# ET6801 register map
Vendor: ETMCU Inc.; File version: v0.0.1
CPU: CM7 r2p1, little endian, MPU, FPU, I-cache, D-cache, ITCM, DTCM, 4 interrupt priority bits
Registers are 32-bit, read-write, reset 0x0 unless marked. A register's access mark holds for its fields unless they carry their own. Offsets are from the block's base; [hi:lo] are bit positions; {n}, {i} and the like mark numbered series.

## NVIC_STIR — Nested vectored interrupt controller
Base 0xE000EF00
0x00 STIR — Software trigger interrupt register
  [8:0] INTID — Software generated interrupt ID

## FPU_CPACR — Floating point unit CPACR
Base 0xE000ED88
0x00 CPACR — Coprocessor access control register
  [23:20] CP

## SCB_ACTRL — System control block ACTLR
Base 0xE000E008
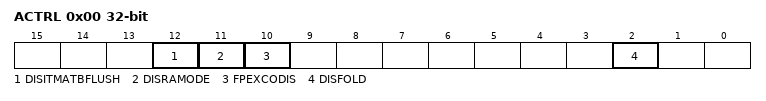
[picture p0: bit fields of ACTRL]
0x00 ACTRL — Auxiliary control register
  [12] DISITMATBFLUSH, [11] DISRAMODE, [10] FPEXCODIS, [2] DISFOLD

## FPU — Floting point unit
Base 0xE000EF34
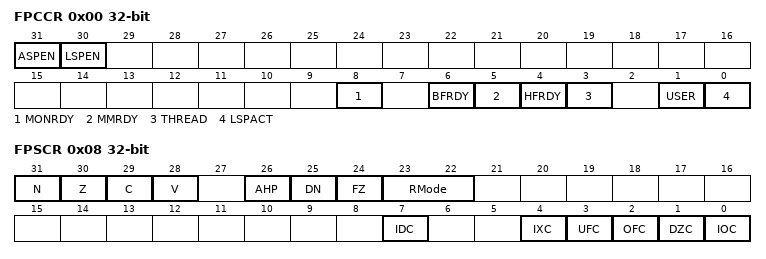
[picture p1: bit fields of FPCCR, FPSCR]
0x00 FPCCR — Floating-point context control register
  [31] ASPEN, [30] LSPEN, [8] MONRDY, [6] BFRDY, [5] MMRDY, [4] HFRDY, [3] THREAD, [1] USER, [0] LSPACT
0x04 FPCAR — Floating-point context address register
  [31:3] ADDRESS — Location of unpopulated floating-point
0x08 FPSCR — Floating-point status control register
  [31] N — Negative condition code flag
  [30] Z — Zero condition code flag
  [29] C — Carry condition code flag
  [28] V — Overflow condition code flag
  [26] AHP — Alternative half-precision control bit
  [25] DN — Default NaN mode control bit
  [24] FZ — Flush-to-zero mode control bit:
  [23:22] RMode — Rounding Mode control field
  [7] IDC — Input denormal cumulative exception bit.
  [4] IXC — Inexact cumulative exception bit
  [3] UFC — Underflow cumulative exception bit
  [2] OFC — Overflow cumulative exception bit
  [1] DZC — Division by zero cumulative exception bit.
  [0] IOC — Invalid operation cumulative exception bit

## PF — Processor features
Base 0xE000ED78
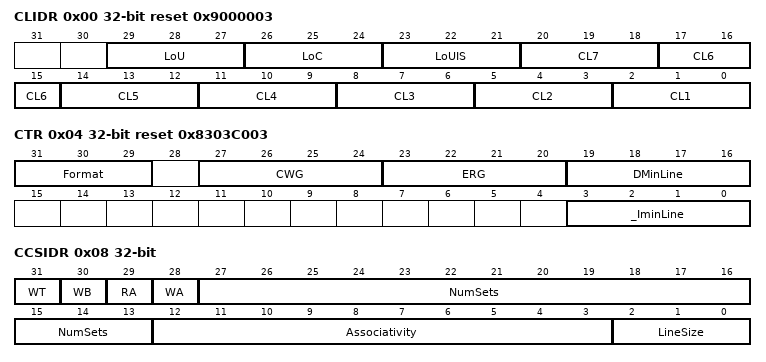
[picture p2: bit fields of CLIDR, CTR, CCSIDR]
0x00 CLIDR ro reset 0x9000003 — Cache Level ID register
  [29:27] LoU, [26:24] LoC, [23:21] LoUIS, [3n-1:3n-3] CL{n} (n=1..7)
0x04 CTR ro reset 0x8303C003 — Cache Type register
  [31:29] Format, [27:24] CWG, [23:20] ERG, [19:16] DMinLine, [3:0] _IminLine
0x08 CCSIDR ro — Cache Size ID register
  [31] WT, [30] WB, [29] RA, [28] WA, [27:13] NumSets, [12:3] Associativity, [2:0] LineSize

## NVIC — Nested Vectored Interrupt Controller
Base 0xE000E100
{0x0+4i} ISER{i} (i=0..3) — Interrupt Set-Enable Register
  [31:0] SETENA
{0x80+4i} ICER{i} (i=0..3) — Interrupt Clear-Enable Register
  [31:0] CLRENA
{0x100+4i} ISPR{i} (i=0..3) — Interrupt Set-Pending Register
  [31:0] SETPEND
{0x180+4i} ICPR{i} (i=0..3) — Interrupt Clear-Pending Register
  [31:0] CLRPEND
{0x200+4i} IABR{i} ro (i=0..3) — Interrupt Active Bit Register
  [31:0] ACTIVE
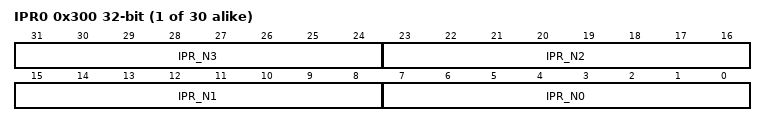
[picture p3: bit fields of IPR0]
{0x300+4i} IPR{i} (i=0..29) — Interrupt Priority Register
  [8n+7:8n] IPR_N{n} (n=0..3)

## MPU — Memory protection unit
Base 0xE000ED90
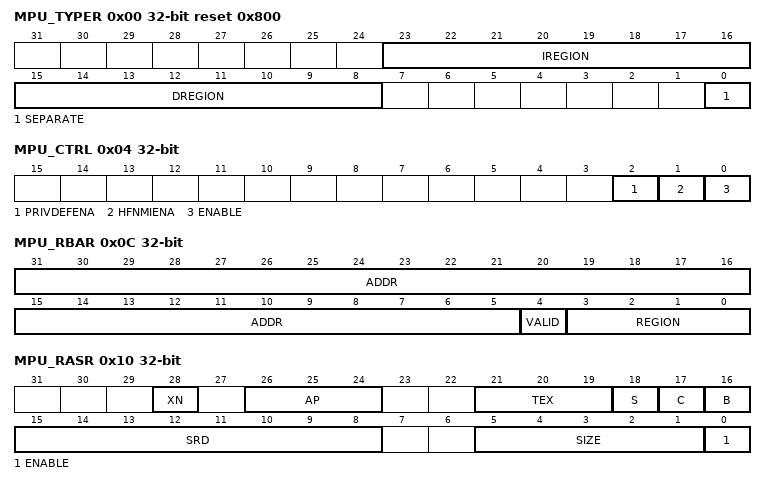
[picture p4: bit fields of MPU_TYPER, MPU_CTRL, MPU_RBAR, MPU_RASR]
0x00 MPU_TYPER ro reset 0x800 — MPU type register
  [23:16] IREGION — Number of MPU instruction regions
  [15:8] DREGION — Number of MPU data regions
  [0] SEPARATE — Separate flag
0x04 MPU_CTRL ro — MPU control register
  [2] PRIVDEFENA — Enable priviliged software access to default memory map
  [1] HFNMIENA — Enables the operation of MPU during hard fault
  [0] ENABLE — Enables the MPU
0x08 MPU_RNR — MPU region number register
  [7:0] REGION — MPU region
0x0C MPU_RBAR — MPU region base address register
  [31:5] ADDR — Region base address field
  [4] VALID — MPU region number valid
  [3:0] REGION — MPU region field
0x10 MPU_RASR — MPU region attribute and size register
  [28] XN — Instruction access disable bit
  [26:24] AP — Access permission
  [21:19] TEX — memory attribute
  [18] S — Shareable memory attribute
  [17] C — memory attribute
  [16] B — memory attribute
  [15:8] SRD — Subregion disable bits
  [5:1] SIZE — Size of the MPU protection region
  [0] ENABLE — Region enable bit.

## SYSTICK — SysTick timer
Base 0xE000E010
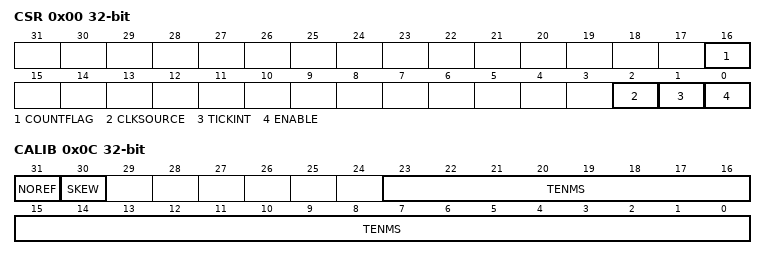
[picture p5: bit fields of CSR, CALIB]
0x00 CSR — SysTick control and status register
  [16] COUNTFLAG
  [2] CLKSOURCE — Clock source selection
  [1] TICKINT — SysTick exception request enable
  [0] ENABLE — Counter enable
0x04 RVR — SysTick reload value register
  [23:0] RELOAD — RELOAD value
0x08 CVR — SysTick current value register
  [23:0] CURRENT — Current counter value
0x0C CALIB — SysTick calibration value register
  [31] NOREF — NOREF flag. Reads as zero
  [30] SKEW — SKEW flag: Indicates whether the TENMS value is exact
  [23:0] TENMS — Calibration value

## SYSCNT_CTRL — Provide an overview of the purpose and functionality of the peripheral: SYSCNT_CTRL
Base 0x4040E000
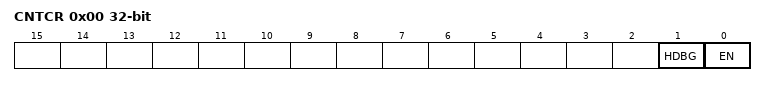
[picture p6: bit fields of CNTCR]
0x00 CNTCR — Describe the details of the register: CNTCR
  [1] HDBG — 1 Halt on Debug, 0 Do not halt on debug
  [0] EN — 1 The counter is enabled and is incrementing, 0 The counter is disabled and not incrementing
0x04 CNTSR ro — Describe the details of the register: CNTSR
  [1] DBGH — Debug Halted
0x08 CNTCVL — Describe the details of the register: CNTCVL
  [31:0] CNTCVL_L — Current value of the timestamp counter, lower 32 bits
0x0C CNTCVU — Describe the details of the register: CNTCVU
  [31:0] CNTCVU_U — Current value of the timestamp counter, upper 32 bits
0x20 CNTFID0 — Describe the details of the register: CNTFID0
  [31:0] FREQ — Frequency in number of ticks per second. You can specify up to 4GHz

## SYSCNT_RO — Provide an overview of the purpose and functionality of the peripheral: SYSCNT_RO
Base 0x4040D000
0x00 CNTCVL — Describe the details of the register: CNTCVL
  [31:0] CNTCVL_L — Current value of the timestamp counter, lower 32 bits
0x04 CNTCVU — Describe the details of the register: CNTCVU
  [31:0] CNTCVU_U — Current value of the timestamp counter, upper 32 bits
